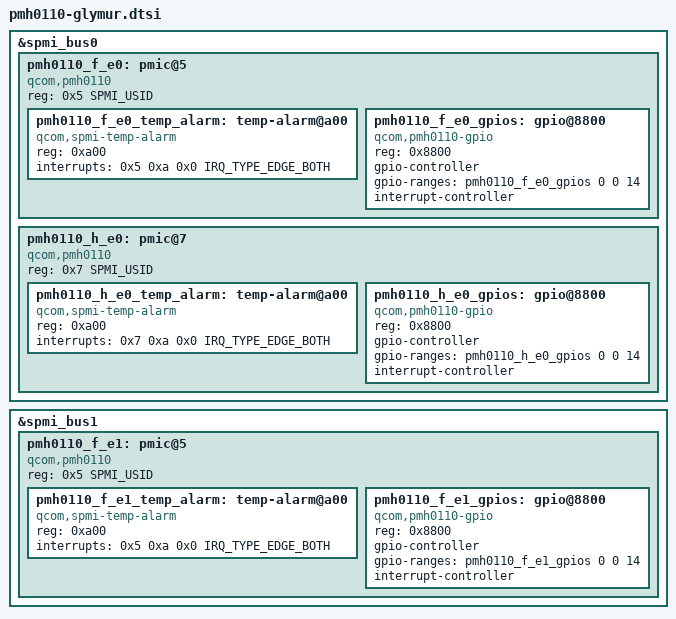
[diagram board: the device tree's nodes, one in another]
// SPDX-License-Identifier: BSD-3-Clause
/*
 * Copyright (c) Qualcomm Technologies, Inc. and/or its subsidiaries.
 */

#include <dt-bindings/interrupt-controller/irq.h>
#include <dt-bindings/spmi/spmi.h>

&spmi_bus0 {
	pmh0110_f_e0: pmic@5 {
		compatible = "qcom,pmh0110", "qcom,spmi-pmic";
		reg = <0x5 SPMI_USID>;
		#address-cells = <1>;
		#size-cells = <0>;

		pmh0110_f_e0_temp_alarm: temp-alarm@a00 {
			compatible = "qcom,spmi-temp-alarm";
			reg = <0xa00>;
			interrupts = <0x5 0xa 0x0 IRQ_TYPE_EDGE_BOTH>;
			#thermal-sensor-cells = <0>;
		};

		pmh0110_f_e0_gpios: gpio@8800 {
			compatible = "qcom,pmh0110-gpio", "qcom,spmi-gpio";
			reg = <0x8800>;
			gpio-controller;
			gpio-ranges = <&pmh0110_f_e0_gpios 0 0 14>;
			#gpio-cells = <2>;
			interrupt-controller;
			#interrupt-cells = <2>;
		};
	};

	pmh0110_h_e0: pmic@7 {
		compatible = "qcom,pmh0110", "qcom,spmi-pmic";
		reg = <0x7 SPMI_USID>;
		#address-cells = <1>;
		#size-cells = <0>;

		pmh0110_h_e0_temp_alarm: temp-alarm@a00 {
			compatible = "qcom,spmi-temp-alarm";
			reg = <0xa00>;
			interrupts = <0x7 0xa 0x0 IRQ_TYPE_EDGE_BOTH>;
			#thermal-sensor-cells = <0>;
		};

		pmh0110_h_e0_gpios: gpio@8800 {
			compatible = "qcom,pmh0110-gpio", "qcom,spmi-gpio";
			reg = <0x8800>;
			gpio-controller;
			gpio-ranges = <&pmh0110_h_e0_gpios 0 0 14>;
			#gpio-cells = <2>;
			interrupt-controller;
			#interrupt-cells = <2>;
		};
	};
};

&spmi_bus1 {
	pmh0110_f_e1: pmic@5 {
		compatible = "qcom,pmh0110", "qcom,spmi-pmic";
		reg = <0x5 SPMI_USID>;
		#address-cells = <1>;
		#size-cells = <0>;

		pmh0110_f_e1_temp_alarm: temp-alarm@a00 {
			compatible = "qcom,spmi-temp-alarm";
			reg = <0xa00>;
			interrupts = <0x5 0xa 0x0 IRQ_TYPE_EDGE_BOTH>;
			#thermal-sensor-cells = <0>;
		};

		pmh0110_f_e1_gpios: gpio@8800 {
			compatible = "qcom,pmh0110-gpio", "qcom,spmi-gpio";
			reg = <0x8800>;
			gpio-controller;
			gpio-ranges = <&pmh0110_f_e1_gpios 0 0 14>;
			#gpio-cells = <2>;
			interrupt-controller;
			#interrupt-cells = <2>;
		};
	};
};
